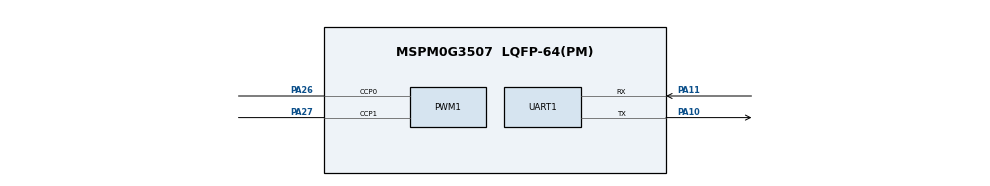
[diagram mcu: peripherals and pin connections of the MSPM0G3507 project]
/**
 * These arguments were used when this file was generated. They will be automatically applied on subsequent loads
 * via the GUI or CLI. Run CLI with '--help' for additional information on how to override these arguments.
 * @cliArgs --device "MSPM0G350X" --part "Default" --package "LQFP-64(PM)" --product "mspm0_sdk@2.10.00.04"
 * @v2CliArgs --device "MSPM0G3507" --package "LQFP-64(PM)" --product "mspm0_sdk@2.10.00.04"
 * @versions {"tool":"1.27.0+4565"}
 */

/**
 * Import the modules used in this configuration.
 */
const GPIO    = scripting.addModule("/ti/driverlib/GPIO", {}, false);
const GPIO1   = GPIO.addInstance();
const GPIO2   = GPIO.addInstance();
const GPIO3   = GPIO.addInstance();
const PWM     = scripting.addModule("/ti/driverlib/PWM", {}, false);
const PWM1    = PWM.addInstance();
const SYSCTL  = scripting.addModule("/ti/driverlib/SYSCTL");
const SYSTICK = scripting.addModule("/ti/driverlib/SYSTICK");
const UART    = scripting.addModule("/ti/driverlib/UART", {}, false);
const UART1   = UART.addInstance();

/**
 * Write custom configuration values to the imported modules.
 */
const divider6       = system.clockTree["PLL_CLK2X_DIV"];
divider6.divideValue = 4;

const divider7       = system.clockTree["PLL_PDIV"];
divider7.divideValue = 2;

const divider9       = system.clockTree["UDIV"];
divider9.divideValue = 2;

const multiplier2         = system.clockTree["PLL_QDIV"];
multiplier2.multiplyValue = 10;

const mux8       = system.clockTree["HSCLKMUX"];
mux8.inputSelect = "HSCLKMUX_SYSPLL2X";

GPIO1.$name                          = "AIN";
GPIO1.port                           = "PORTA";
GPIO1.associatedPins.create(2);
GPIO1.associatedPins[0].$name        = "AIN1";
GPIO1.associatedPins[0].initialValue = "SET";
GPIO1.associatedPins[0].assignedPin  = "24";
GPIO1.associatedPins[1].$name        = "AIN2";
GPIO1.associatedPins[1].initialValue = "SET";
GPIO1.associatedPins[1].assignedPin  = "25";

const Board = scripting.addModule("/ti/driverlib/Board", {}, false);

GPIO2.$name                          = "BIN";
GPIO2.port                           = "PORTB";
GPIO2.associatedPins.create(2);
GPIO2.associatedPins[0].initialValue = "SET";
GPIO2.associatedPins[0].assignedPin  = "25";
GPIO2.associatedPins[0].$name        = "BIN1";
GPIO2.associatedPins[1].$name        = "BIN2";
GPIO2.associatedPins[1].initialValue = "SET";
GPIO2.associatedPins[1].assignedPin  = "24";

GPIO3.$name                          = "LED";
GPIO3.associatedPins[0].$name        = "LED1";
GPIO3.associatedPins[0].initialValue = "SET";
GPIO3.associatedPins[0].assignedPort = "PORTB";
GPIO3.associatedPins[0].assignedPin  = "22";

PWM1.$name                              = "PWM";
PWM1.timerCount                         = 4000;
PWM1.timerStartTimer                    = true;
PWM1.peripheral.$assign                 = "TIMG7";
PWM1.peripheral.ccp0Pin.$assign         = "PA26";
PWM1.peripheral.ccp1Pin.$assign         = "PA27";
PWM1.PWM_CHANNEL_0.$name                = "ti_driverlib_pwm_PWMTimerCC0";
PWM1.PWM_CHANNEL_0.ccValue              = 2000;
PWM1.PWM_CHANNEL_0.invert               = true;
PWM1.PWM_CHANNEL_1.$name                = "ti_driverlib_pwm_PWMTimerCC1";
PWM1.PWM_CHANNEL_1.invert               = true;
PWM1.PWM_CHANNEL_1.ccValue              = 2000;
PWM1.ccp0PinConfig.$name                = "ti_driverlib_gpio_GPIOPinGeneric0";
PWM1.ccp0PinConfig.direction            = scripting.forceWrite("OUTPUT");
PWM1.ccp0PinConfig.hideOutputInversion  = scripting.forceWrite(false);
PWM1.ccp0PinConfig.onlyInternalResistor = scripting.forceWrite(false);
PWM1.ccp0PinConfig.passedPeripheralType = scripting.forceWrite("Digital");
PWM1.ccp1PinConfig.$name                = "ti_driverlib_gpio_GPIOPinGeneric1";
PWM1.ccp1PinConfig.direction            = scripting.forceWrite("OUTPUT");
PWM1.ccp1PinConfig.hideOutputInversion  = scripting.forceWrite(false);
PWM1.ccp1PinConfig.onlyInternalResistor = scripting.forceWrite(false);
PWM1.ccp1PinConfig.passedPeripheralType = scripting.forceWrite("Digital");

SYSCTL.forceDefaultClkConfig = true;
SYSCTL.clockTreeEn           = true;

SYSTICK.periodEnable    = true;
SYSTICK.interruptEnable = true;
SYSTICK.period          = 80000;
SYSTICK.systickEnable   = true;

UART1.$name                            = "UART0";
UART1.targetBaudRate                   = 115200;
UART1.peripheral.$assign               = "UART0";
UART1.peripheral.rxPin.$assign         = "PA11";
UART1.peripheral.txPin.$assign         = "PA10";
UART1.txPinConfig.$name                = "ti_driverlib_gpio_GPIOPinGeneric2";
UART1.txPinConfig.direction            = scripting.forceWrite("OUTPUT");
UART1.txPinConfig.hideOutputInversion  = scripting.forceWrite(false);
UART1.txPinConfig.onlyInternalResistor = scripting.forceWrite(false);
UART1.txPinConfig.passedPeripheralType = scripting.forceWrite("Digital");
UART1.rxPinConfig.$name                = "ti_driverlib_gpio_GPIOPinGeneric3";
UART1.rxPinConfig.hideOutputInversion  = scripting.forceWrite(false);
UART1.rxPinConfig.onlyInternalResistor = scripting.forceWrite(false);
UART1.rxPinConfig.passedPeripheralType = scripting.forceWrite("Digital");

/**
 * Pinmux solution for unlocked pins/peripherals. This ensures that minor changes to the automatic solver in a future
 * version of the tool will not impact the pinmux you originally saw.  These lines can be completely deleted in order to
 * re-solve from scratch.
 */
GPIO1.associatedPins[0].pin.$suggestSolution = "PA24";
GPIO1.associatedPins[1].pin.$suggestSolution = "PA25";
Board.peripheral.$suggestSolution            = "DEBUGSS";
Board.peripheral.swclkPin.$suggestSolution   = "PA20";
Board.peripheral.swdioPin.$suggestSolution   = "PA19";
GPIO2.associatedPins[0].pin.$suggestSolution = "PB25";
GPIO2.associatedPins[1].pin.$suggestSolution = "PB24";
GPIO3.associatedPins[0].pin.$suggestSolution = "PB22";
